# STM32L4P5 register map
File version: 1.8
CPU: CM4 r0p1, little endian, MPU, FPU, 4 interrupt priority bits
Registers are 32-bit, read-write, reset 0x0 unless marked. A register's access mark holds for its fields unless they carry their own. Offsets are from the block's base; [hi:lo] are bit positions; lines under a group give offsets from that group; {n}, {i} and the like mark numbered series.

## LTDC — LCD-TFT display controller
Base 0x40016800
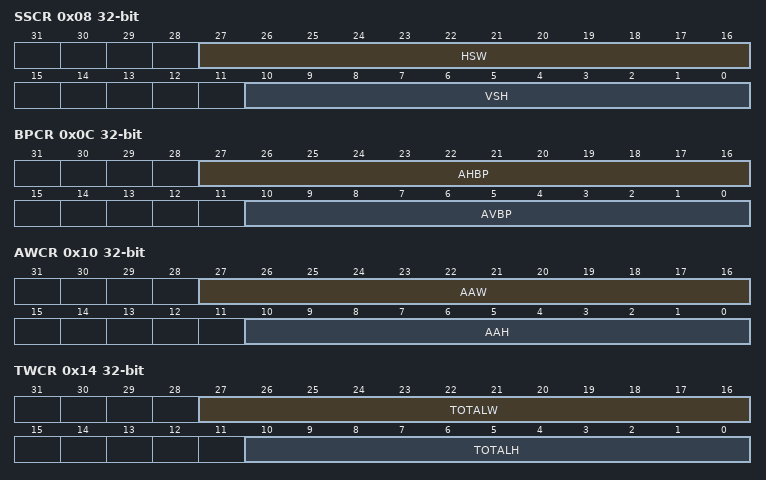
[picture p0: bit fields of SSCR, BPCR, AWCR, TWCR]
0x08 SSCR — LTDC Synchronization Size Configuration Register
  [27:16] HSW — Horizontal Synchronization Width (in units of pixel clock period)
  [10:0] VSH — Vertical Synchronization Height (in units of horizontal scan line)
0x0C BPCR — LTDC Back Porch Configuration Register
  [27:16] AHBP — Accumulated Horizontal back porch (in units of pixel clock period)
  [10:0] AVBP — Accumulated Vertical back porch (in units of horizontal scan line)
0x10 AWCR — LTDC Active Width Configuration Register
  [27:16] AAW — Accumulated Active Width (in units of pixel clock period)
  [10:0] AAH — Accumulated Active Height (in units of horizontal scan line)
0x14 TWCR — LTDC Total Width Configuration Register
  [27:16] TOTALW — Total Width (in units of pixel clock period)
  [10:0] TOTALH — Total Height (in units of horizontal scan line)
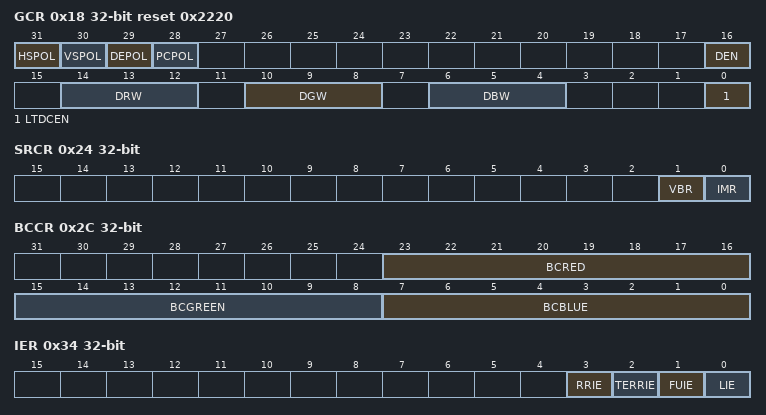
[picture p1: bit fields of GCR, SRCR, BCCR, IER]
0x18 GCR access per field reset 0x2220 — LTDC Global Control Register
  [31] HSPOL rw — Horizontal Synchronization Polarity
    0=ActiveLow (Horizontal synchronization polarity is active low); 1=ActiveHigh (Horizontal synchronization polarity is active high)
  [30] VSPOL rw — Vertical Synchronization Polarity
    0=ActiveLow (Vertical synchronization polarity is active low); 1=ActiveHigh (Vertical synchronization polarity is active high)
  [29] DEPOL rw — Not Data Enable Polarity
    0=ActiveLow (Data enable polarity is active low); 1=ActiveHigh (Data enable polarity is active high)
  [28] PCPOL rw — Pixel Clock Polarity
    0=RisingEdge (Pixel clock on rising edge); 1=FallingEdge (Pixel clock on falling edge)
  [16] DEN rw — Dither Enable
    0=Disabled (Dither disabled); 1=Enabled (Dither enabled)
  [14:12] DRW ro — Dither Red Width
  [10:8] DGW ro — Dither Green Width
  [6:4] DBW ro — Dither Blue Width
  [0] LTDCEN rw — LCD-TFT controller enable bit
    0=Disabled (LCD-TFT controller disabled); 1=Enabled (LCD-TFT controller enabled)
0x24 SRCR — LTDC Shadow Reload Configuration Register
  [1] VBR — Vertical Blanking Reload
    0=NoEffect (This bit is set by software and cleared only by hardware after reload (it cannot be cleared through register write once it is set)); 1=Reload (The shadow registers are reloaded during the vertical blanking period (at the beginning of the first line after the active display area).)
  [0] IMR — Immediate Reload
    0=NoEffect (This bit is set by software and cleared only by hardware after reload (it cannot be cleared through register write once it is set)); 1=Reload (The shadow registers are reloaded immediately. This bit is set by software and cleared only by hardware after reload)
0x2C BCCR — LTDC Background Color Configuration Register
  [23:16] BCRED — Background Color Red value
  [15:8] BCGREEN — Background Color Green value
  [7:0] BCBLUE — Background Color Blue value
0x34 IER — LTDC Interrupt Enable Register
  [3] RRIE — Register Reload interrupt enable
    0=Disabled (Register reload interrupt disabled); 1=Enabled (Register reload interrupt enabled)
  [2] TERRIE — Transfer Error Interrupt Enable
    0=Disabled (Transfer error interrupt disabled); 1=Enabled (Transfer error interrupt enabled)
  [1] FUIE — FIFO Underrun Interrupt Enable
    0=Disabled (FIFO underrun interrupt disabled); 1=Enabled (FIFO underrun interrupt enabled)
  [0] LIE — Line Interrupt Enable
    0=Disabled (Line interrupt disabled); 1=Enabled (Line interrupt enabled)
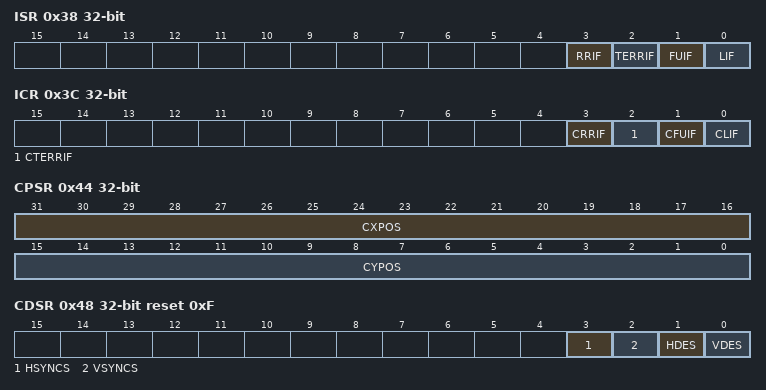
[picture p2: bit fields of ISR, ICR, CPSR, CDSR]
0x38 ISR ro — LTDC Interrupt Status Register
  [3] RRIF — Register Reload Interrupt Flag
    0=NoReload (No register reload); 1=Reload (Register reload interrupt generated when a vertical blanking reload occurs (and the first line after the active area is reached))
  [2] TERRIF — Transfer Error interrupt flag
    0=NoError (No transfer error); 1=Error (Transfer error interrupt generated when a bus error occurs)
  [1] FUIF — FIFO Underrun Interrupt flag
    0=NoUnderrun (No FIFO underrun); 1=Underrun (FIFO underrun interrupt generated, if one of the layer FIFOs is empty and pixel data is read from the FIFO)
  [0] LIF — Line Interrupt flag
    0=NotReached (Programmed line not reached); 1=Reached (Line interrupt generated when a programmed line is reached)
0x3C ICR wo — LTDC Interrupt Clear Register
  [3] CRRIF write-1-clears — Clears Register Reload Interrupt Flag
    1=Clears the RRIF flag in the ISR register
  [2] CTERRIF write-1-clears — Clears the Transfer Error Interrupt Flag
    1=Clears the TERRIF flag in the ISR register
  [1] CFUIF write-1-clears — Clears the FIFO Underrun Interrupt flag
    1=Clears the FUIF flag in the ISR register
  [0] CLIF write-1-clears — Clears the Line Interrupt Flag
    1=Clears the LIF flag in the ISR register
0x40 LIPCR — LTDC Line Interrupt Position Configuration Register
  [10:0] LIPOS — Line Interrupt Position
0x44 CPSR ro — LTDC Current Position Status Register
  [31:16] CXPOS — Current X Position
  [15:0] CYPOS — Current Y Position
0x48 CDSR ro reset 0xF — LTDC Current Display Status Register
  [3] HSYNCS — Horizontal Synchronization display Status
    0=NotActive (Currently not in HSYNC phase); 1=Active (Currently in HSYNC phase)
  [2] VSYNCS — Vertical Synchronization display Status
    0=NotActive (Currently not in VSYNC phase); 1=Active (Currently in VSYNC phase)
  [1] HDES — Horizontal Data Enable display Status
    0=NotActive (Currently not in horizontal Data Enable phase); 1=Active (Currently in horizontal Data Enable phase)
  [0] VDES — Vertical Data Enable display Status
    0=NotActive (Currently not in vertical Data Enable phase); 1=Active (Currently in vertical Data Enable phase)
{0x4+0x80*i} LAYER{i} (i=1..2) group — Cluster LAYER{i}, containing L?CR, L?WHPCR, L?WVPCR, L?CKCR, L?PFCR, L?CACR, L?DCCR, L?BFCR, L?CFBAR, L?CFBLR, L?CFBLNR, L?CLUTWR
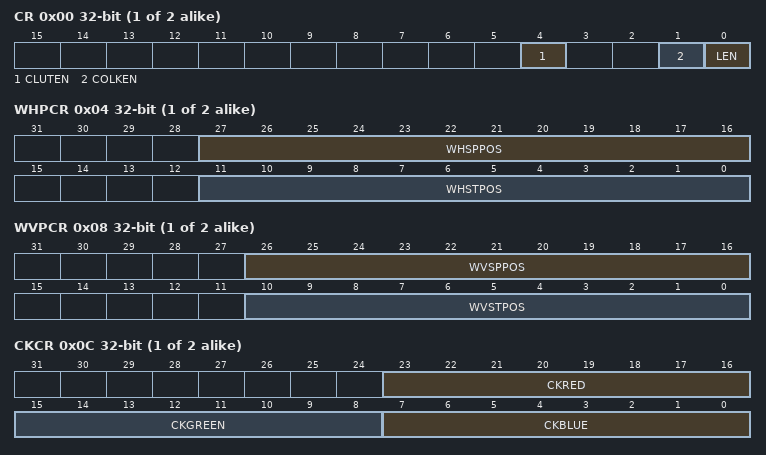
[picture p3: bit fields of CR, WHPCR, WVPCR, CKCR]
  0x00 CR — LTDC Layer Control Register
    [4] CLUTEN — Color Look-Up Table Enable
      0=Disabled (Color look-up table disabled); 1=Enabled (Color look-up table enabled)
    [1] COLKEN — Color Keying Enable
      0=Disabled (Color keying disabled); 1=Enabled (Color keying enabled)
    [0] LEN — Layer Enable
      0=Disabled (Layer disabled); 1=Enabled (Layer enabled)
  0x04 WHPCR — LTDC Layer Window Horizontal Position Configuration Register
    [27:16] WHSPPOS — Window Horizontal Stop Position
    [11:0] WHSTPOS — Window Horizontal Start Position
  0x08 WVPCR — LTDC Layer Window Vertical Position Configuration Register
    [26:16] WVSPPOS — Window Vertical Stop Position
    [10:0] WVSTPOS — Window Vertical Start Position
  0x0C CKCR — LTDC Layer Color Keying Configuration Register
    [23:16] CKRED — Color Key Red value
    [15:8] CKGREEN — Color Key Green value
    [7:0] CKBLUE — Color Key Blue value
  0x10 PFCR — LTDC Layer Pixel Format Configuration Register
    [2:0] PF — Pixel Format
      0=ARGB8888; 1=RGB888; 2=RGB565; 3=ARGB1555; 4=ARGB4444; 5=L8 (L8 (8-bit luminance)); 6=AL44 (AL44 (4-bit alpha, 4-bit luminance)); 7=AL88 (AL88 (8-bit alpha, 8-bit luminance))
  0x14 CACR — LTDC Layer Constant Alpha Configuration Register
    [7:0] CONSTA — Constant Alpha
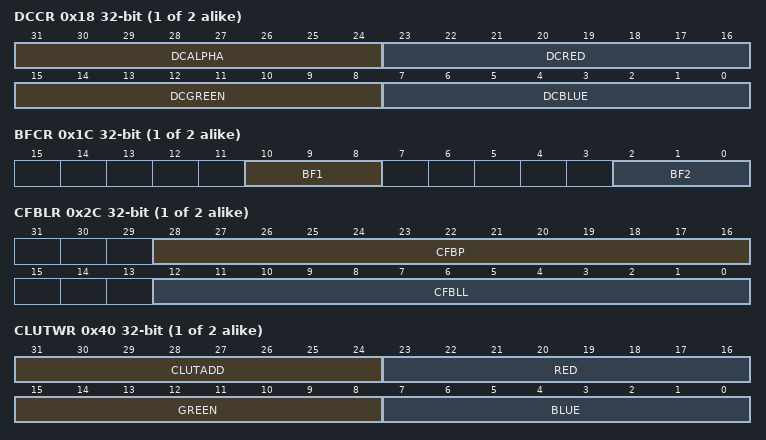
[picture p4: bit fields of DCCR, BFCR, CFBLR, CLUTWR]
  0x18 DCCR — LTDC Layer Default Color Configuration Register
    [31:24] DCALPHA — Default Color Alpha
    [23:16] DCRED — Default Color Red
    [15:8] DCGREEN — Default Color Green
    [7:0] DCBLUE — Default Color Blue
  0x1C BFCR — LTDC Layer Blending Factors Configuration Register
    [10:8] BF1 — Blending Factor 1
      4=Constant (BF1 = constant alpha); 6=Pixel (BF1 = pixel alpha * constant alpha)
    [2:0] BF2 — Blending Factor 2
      5=Constant (BF2 = 1 - constant alpha); 7=Pixel (BF2 = 1 - pixel alpha * constant alpha)
  0x28 CFBAR — LTDC Layer Color Frame Buffer Address Register
    [31:0] CFBADD — Color Frame Buffer Start Address
  0x2C CFBLR — LTDC Layer Color Frame Buffer Length Register
    [28:16] CFBP — Color Frame Buffer Pitch in bytes
    [12:0] CFBLL — Color Frame Buffer Line Length
  0x30 CFBLNR — LTDC Layer ColorFrame Buffer Line Number Register
    [10:0] CFBLNBR — Frame Buffer Line Number
  0x40 CLUTWR wo — LTDC Layerx CLUT Write Register
    [31:24] CLUTADD — CLUT Address
    [23:16] RED — Red value
    [15:8] GREEN — Green value
    [7:0] BLUE — Blue value
